# PIC32MZ1025W104132 device description
Architecture: MIPS; Family: PIC32MZW; Series: PIC32MZW
Registers are 32-bit, read-write, no defined reset value unless marked. A register's access mark holds for its fields unless they carry their own. Offsets are from the block's base; [hi:lo] are bit positions; {n}, {i} and the like mark numbered series; 'fields as' and 'values as' point back to an identical list.

## JTAG
Instances: JTAG 0x1f812000 in periph_pb1b
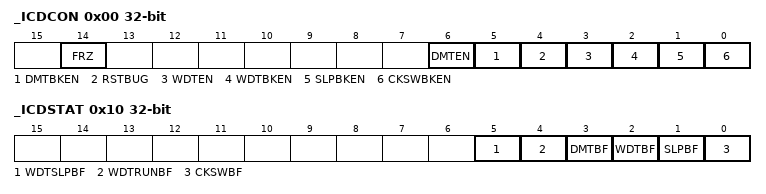
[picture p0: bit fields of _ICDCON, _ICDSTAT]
0x00 _ICDCON
  [14] FRZ, [6] DMTEN, [5] DMTBKEN, [4] RSTBUG, [3] WDTEN, [2] WDTBKEN, [1] SLPBKEN, [0] CKSWBKEN
0x10 _ICDSTAT
  [5] WDTSLPBF, [4] WDTRUNBF, [3] DMTBF, [2] WDTBF, [1] SLPBF, [0] CKSWBF

## LVD
Instances: LVD 0x1f801400 in periph_pb1a
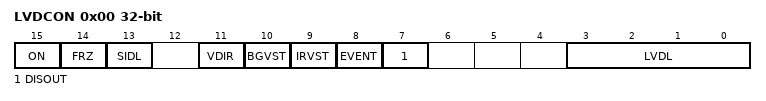
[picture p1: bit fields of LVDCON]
0x00 LVDCON
  [15] ON, [14] FRZ, [13] SIDL, [11] VDIR, [10] BGVST, [9] IRVST, [8] EVENT, [7] DISOUT, [3:0] LVDL

## NVM
Instances: NVM 0x1f800600 in periph_pb1a
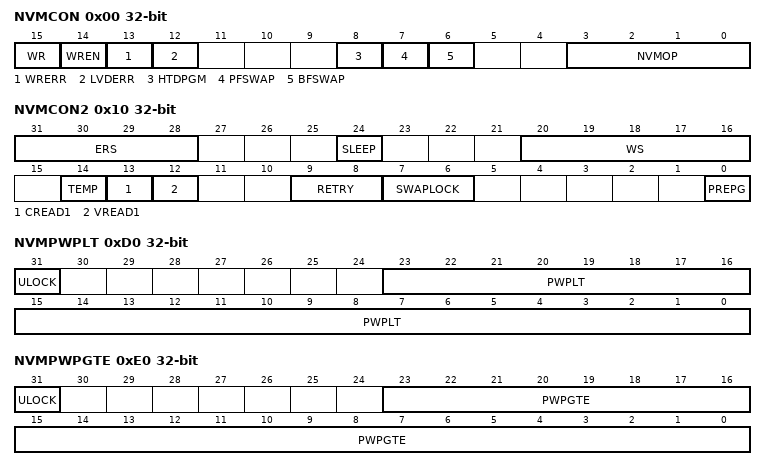
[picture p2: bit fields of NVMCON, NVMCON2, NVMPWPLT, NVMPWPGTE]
0x00 NVMCON — PROGRAMMING CONTROL REGISTER
  [15] WR — Write Control bit
    1=Initiate a Flash operation; 0=Flash operation is complete or inactive
  [14] WREN — Write Enable bit
    1=Enable writes to the WR bit and disables writes to the NVMOP bits; 0=Disable writes to WR bit and enables writes to the NVMOP bits
  [13] WRERR — Write Error bit
    1=Program or erase sequence did not complete successfully; 0=Program or erase sequence completed normally
  [12] LVDERR — Low-Voltage Detect Error bit
    1=Low-voltage detected (possible data corruption; 0=Voltage level is acceptable for programming
  [8] HTDPGM — High Temperature Detected during Program/Erase Operation Bit
    1=High Temp Detected; 0=High Temp Not Detected
  [7] PFSWAP — Program Flash Bank Swap Control bit
    1=Program Flash Bank 2 is mapped to the lower mapped region and program Flash Bank 1 is mapped to the upper mapped region; 0=Program Flash Bank 1 is mapped to the lower mapped region and program Flash Bank 2 is mapped to the upper mapped region
  [6] BFSWAP — Boot Flash Bank Alias Swap Control bit
    1=Boot Flash Bank 2 is mapped to the lower boot alias and boot Flash Bank 1 is mapped to the upper boot alias; 0=Boot Flash Bank 1 is mapped to the lower boot alias and boot Flash Bank 2 is mapped to the upper boot alias
  [3:0] NVMOP — NVM Operation bits
    3=Program erase operation: erase all of program Flash memory (all pages must be unprotected; 6=Upper program Flash memory erase operation: erases only the upper mapped region of program Flash (all pages in that region must be unprotected); 5=Lower program Flash memory erase operation: erases only the lower mapped region of program Flash (all pages in that region must be unprotected); 4=Page erase operation: erases page selected by NVMADDR; 3=Row program operation: programs row selected by NVMADDR; 2=Quad Word (128-bit) program operation: programs the 128-bit Flash word selected by NVMADDR; 1=Word program operation: programs word selected by NVMADDR; 0=No operation
0x10 NVMCON2 — PROGRAMMING CONTROL 2 REGISTER
  [31:28] ERS
  [24] SLEEP
  [20:16] WS
  [14] TEMP
  [13] CREAD1
  [12] VREAD1
  [9:8] RETRY
  [7:6] SWAPLOCK — Flash Memory Swap Lock Control bits
    3=PFSWAP and BFSWAP are not writable and SWAPLOCK is not writable; 2=PFSWAP and BFSWAP are not writable and SWAPLOCK is writable; 1=PFSWAP and BFSWAP are not writable and SWAPLOCK is writable; 0=PFSWAP and BFSWAP are writable and SWAPLOCK is writable
  [0] PREPG — NVM Pre-Program Control Bit
    1=Program Operations include Pre-Program step; 0=Program Operations exclude Pre-Program step
0x20 NVMKEY wo — Programming Unlock Register
0x30 NVMADDR — Flash Address Register
{0x40+0x10*i} NVMDATA{i} (i=0..3) — Flash Data Register (x = 0-3
{0x40+0x10*i} NVMDATA{i} (i=4..7) — Flash Data Register
  [31:0] NVMDATA3
0xC0 NVMSRCADDR — Source Data Address Register
0xD0 NVMPWPLT — FLASH PROGRAM WRITE PROTECT (WATERMARK) REGISTER
  [31] ULOCK — NVMPWPLT Register Unlock Bit
    1=Register is not locked and can be modified; 0=Register is locked and cannot be modified
  [23:0] PWPLT
0xE0 NVMPWPGTE — FLASH PROGRAM WRITE PROTECT
  [31] ULOCK — Program Flash Memory Page Write-protect Unlock bit
    values as NVMPWPLT.ULOCK
  [23:0] PWPGTE
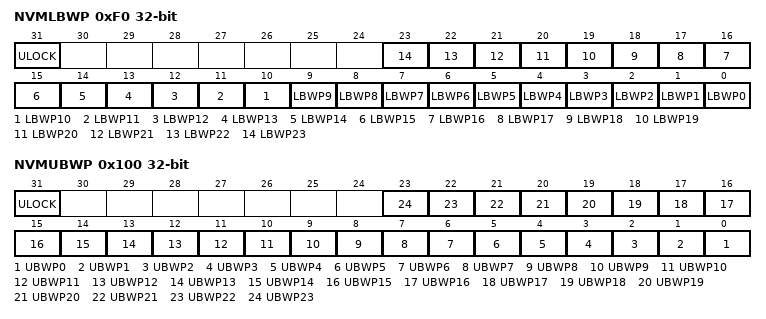
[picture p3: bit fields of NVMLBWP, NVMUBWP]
0xF0 NVMLBWP — Program Flash Write-Protect Register
  [31] ULOCK, [n] LBWP{n} (n=0..23)
0x100 NVMUBWP
  [31] ULOCK, [n] UBWP{n} (n=0..23)
